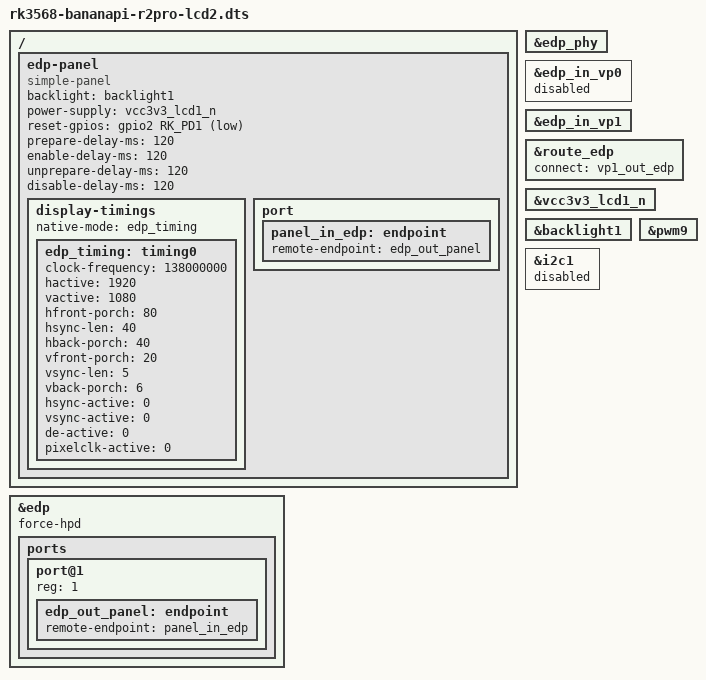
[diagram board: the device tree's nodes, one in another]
// SPDX-License-Identifier: (GPL-2.0+ OR MIT)
/*
 * Copyright (c) 2020 Rockchip Electronics Co., Ltd.
 *
 * 13.3 inch 1920x1080 eDP M133X30-56 for eDP.
 */

/dts-v1/;

#include <dt-bindings/gpio/gpio.h>
#include <dt-bindings/pinctrl/rockchip.h>
#include "rk3568-bananapi-r2pro.dtsi"

/ {
	edp-panel {
		compatible = "simple-panel";
		backlight = <&backlight1>;
		power-supply = <&vcc3v3_lcd1_n>;
		reset-gpios = <&gpio2 RK_PD1 GPIO_ACTIVE_LOW>;
		prepare-delay-ms = <120>;
		enable-delay-ms = <120>;
		unprepare-delay-ms = <120>;
		disable-delay-ms = <120>;

		display-timings {
			native-mode = <&edp_timing>;

			edp_timing: timing0 {
				clock-frequency = <138000000>;
				hactive = <1920>;
				vactive = <1080>;
				hfront-porch = <80>;
				hsync-len = <40>;
				hback-porch = <40>;
				vfront-porch = <20>;
				vsync-len = <5>;
				vback-porch = <6>;
				hsync-active = <0>;
				vsync-active = <0>;
				de-active = <0>;
				pixelclk-active = <0>;
			};
		};

		port {
			panel_in_edp: endpoint {
				remote-endpoint = <&edp_out_panel>;
			};
		};
	};
};

&edp {
	status = "okay";
	force-hpd;

	ports {
		port@1 {
			reg = <1>;

			edp_out_panel: endpoint {
				remote-endpoint = <&panel_in_edp>;
			};
		};
	};
};

&edp_phy {
	status = "okay";
};

&edp_in_vp0 {
	status = "disabled";
};

&edp_in_vp1 {
	status = "okay";
};

&route_edp {
	connect = <&vp1_out_edp>;
	status = "okay";
};

&vcc3v3_lcd1_n {
	status = "okay";
};

&backlight1 {
        status = "okay";
};

&pwm9 {
        status = "okay";
};

&i2c1 {
	status = "disabled";
};
